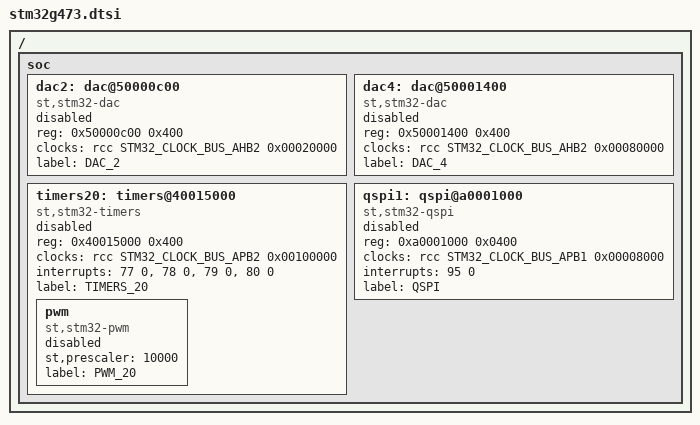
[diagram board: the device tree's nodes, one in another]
/*
 * Copyright (c) 2019 STMicroelectronics.
 *
 * SPDX-License-Identifier: Apache-2.0
 */

#include <st/g4/stm32g4.dtsi>

/ {
	soc {
		dac2: dac@50000c00 {
			compatible = "st,stm32-dac";
			reg = <0x50000c00 0x400>;
			clocks = <&rcc STM32_CLOCK_BUS_AHB2 0x00020000>;
			status = "disabled";
			label = "DAC_2";
			#io-channel-cells = <1>;
		};

		dac4: dac@50001400 {
			compatible = "st,stm32-dac";
			reg = <0x50001400 0x400>;
			clocks = <&rcc STM32_CLOCK_BUS_AHB2 0x00080000>;
			status = "disabled";
			label = "DAC_4";
			#io-channel-cells = <1>;
		};
		
		timers20: timers@40015000 {
			compatible = "st,stm32-timers";
			reg = <0x40015000 0x400>;							/* RM0440 ref manual: Pg. 83, table 3 */
			clocks = <&rcc STM32_CLOCK_BUS_APB2 0x00100000>;	/* RM0440 ref manual: Pg. 316, sec. 7.4.19 */
			interrupts = <77 0>, <78 0>, <79 0>, <80 0>;		/* RM0440 ref manual: Pg. 445, table 97 */
			interrupt-names = "brk", "up", "trgcom", "cc";
			status = "disabled";
			label = "TIMERS_20";

			pwm {
				compatible = "st,stm32-pwm";
				status = "disabled";
				st,prescaler = <10000>;
				label = "PWM_20";
				#pwm-cells = <3>;
			};
		};
		
		qspi1: qspi@a0001000 {
			compatible = "st,stm32-qspi";
			#address-cells = <1>;
			#size-cells = <0>;
			reg = <0xa0001000 0x0400>;							/* RM0440 ref manual: Pg. 82, table 3 */
			clocks = <&rcc STM32_CLOCK_BUS_APB1 0x00008000>;	/* todo: clock bus and register value */
			interrupts = <95 0>;								/* RM0440 ref manual: Pg. 445, table 97 */
			status = "disabled";
			label = "QSPI";
		};
	};
};
